VERSION ""

NS_ :

BS_:
BU_: XXX
BO_ 117 NI1: 8 XXX
   SG_ NI1_Counter : 7|16@0+ (1,0) [0|65535] "" XXX
   SG_ NI1_NI1 : 39|16@0+ (1,0) [1|100000] "" XXX

BO_ 576 Steering: 8 XXX
   SG_ SteeringCorrSignalX : 39|16@0+ (1,-32512) [0|50002] "" XXX
   SG_ Steering : 7|16@0+ (1,-32512) [0|31998] "" XXX

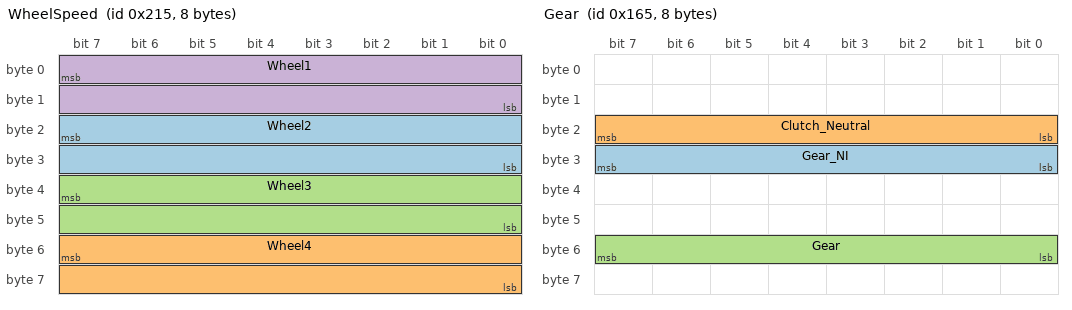
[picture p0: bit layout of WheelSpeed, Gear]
BO_ 533 WheelSpeed: 8 XXX
   SG_ Wheel2 : 23|16@0+ (1,-10000) [0|15000] "" XXX
   SG_ Wheel4 : 55|16@0+ (1,-10000) [0|1] "" XXX
   SG_ Wheel3 : 39|16@0+ (1,-10000) [0|65535] "" XXX
   SG_ Wheel1 : 7|16@0+ (1,-10000) [0|1] "" XXX

BO_ 118 NI2: 8 XXX
   SG_ NI2_Counter : 7|8@0+ (1,0) [0|1] "" XXX
   SG_ NI2_NI : 31|8@0+ (1,0) [0|1] "" XXX

BO_ 357 Gear: 8 XXX
   SG_ Gear_NI : 31|8@0+ (1,0) [0|1] "" XXX
   SG_ Clutch_Neutral : 23|8@0+ (1,0) [0|255] "" XXX
   SG_ Gear : 55|8@0+ (1,0) [0|1] "" XXX

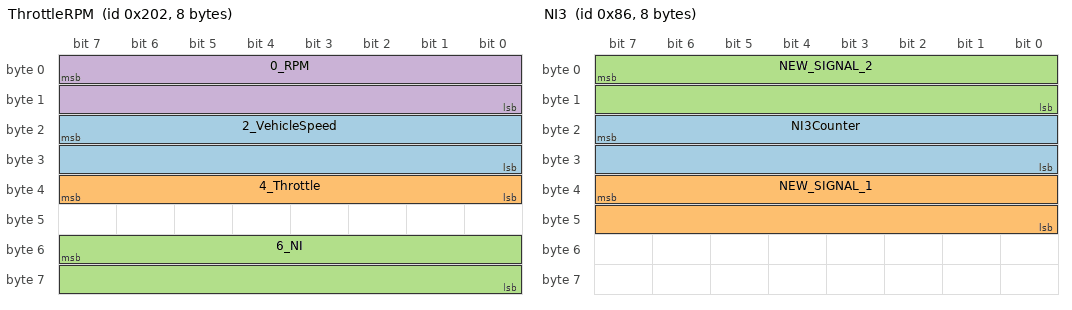
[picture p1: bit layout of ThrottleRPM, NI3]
BO_ 514 ThrottleRPM: 8 XXX
   SG_ 2_VehicleSpeed : 23|16@0+ (1,0) [0|255] "" XXX
   SG_ 4_Throttle : 39|8@0+ (0.4,0) [0|1] "" XXX
   SG_ 6_NI : 55|16@0+ (1,0) [0|1] "" XXX
   SG_ 0_RPM : 7|16@0+ (0.25,0) [0|10000] "" XXX

BO_ 134 NI3: 8 XXX
   SG_ NI3Counter : 23|16@0+ (1,0) [0|1] "" XXX
   SG_ NEW_SIGNAL_1 : 39|16@0+ (1,0) [0|65535] "" XXX
   SG_ NEW_SIGNAL_2 : 7|16@0+ (1,0) [0|100000] "" XXX

BO_ 130 NI5: 8 XXX
   SG_ NEW_SIGNAL_1 : 39|16@0+ (1,0) [0|1] "" XXX

BO_ 284 NI4: 8 XXX

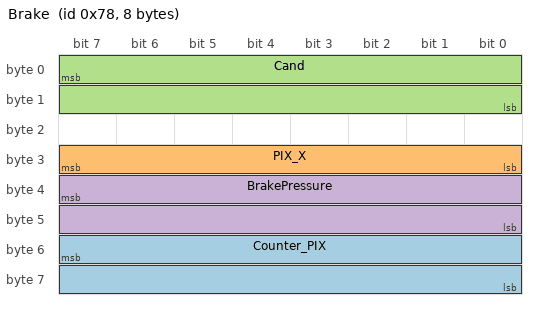
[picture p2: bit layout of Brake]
BO_ 120 Brake: 8 XXX
   SG_ Counter_PIX : 55|16@0+ (1,0) [0|1e+07] "" XXX
   SG_ PIX_X : 31|8@0+ (1,0) [0|1e+07] "" XXX
   SG_ Cand : 7|16@0+ (1,0) [0|100000] "" XXX
   SG_ BrakePressure : 39|16@0+ (1,0) [2|100000] "" XXX

BO_ 121 NI7: 8 XXX

BO_ 253 NEW_MSG_1: 8 XXX

BO_ 304 PI3: 8 XXX
   SG_ GearCand2 : 47|8@0+ (1,0) [0|1] "" XXX
   SG_ NEW_SIGNAL_1 : 55|8@0+ (1,0) [0|1] "" XXX

BO_ 535 NEW_MSG_2: 8 XXX
   SG_ NEW_SIGNAL_1 : 39|1@0+ (1,0) [0|1] "" XXX

BO_ 542 NEW_MSG_3: 8 XXX
   SG_ NEW_SIGNAL_1 : 55|1@0+ (1,0) [0|1] "" XXX

BO_ 358 GearRelated: 8 XXX
   SG_ NEW_SIGNAL_1 : 7|16@0+ (1,0) [0|1] "" XXX
   SG_ NEW_SIGNAL_2 : 23|8@0+ (1,0) [0|255] "" XXX

BO_ 2147484704 Temps: 8 XXX
   SG_ 0_CoolantTempC : 7|8@0+ (1,30) [0|1] "" Vector__XXX

CM_ SG_ 357 Gear "Potentially more info embedded - these are the steady state levels which seem to correlate to gear state.";
BA_DEF_ BO_ "GenMsgBackgroundColor" STRING ;
BA_DEF_ BO_ "GenMsgForegroundColor" STRING ;
BA_DEF_DEF_ "GenMsgBackgroundColor" "#ffffff";
BA_DEF_DEF_ "GenMsgForegroundColor" "#000000";
